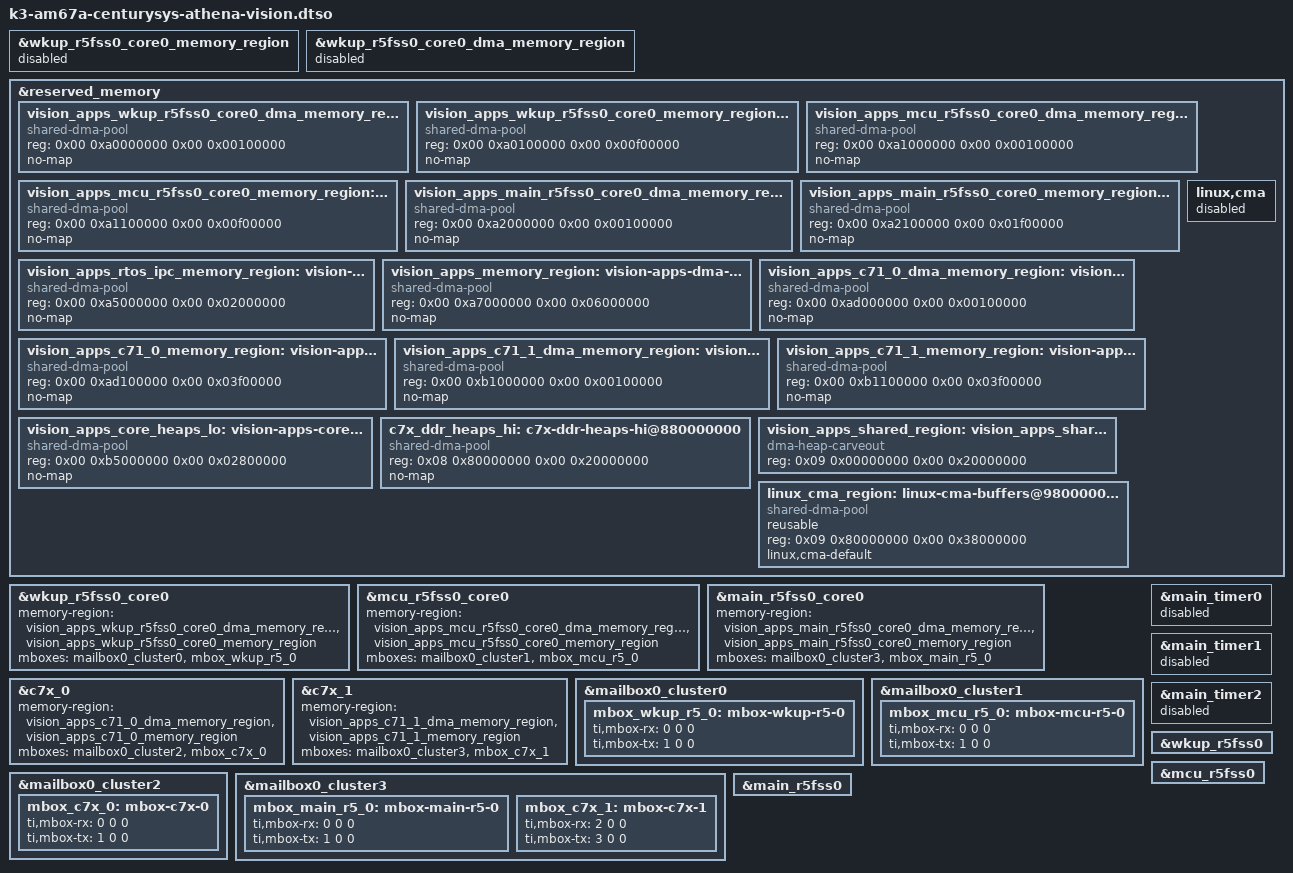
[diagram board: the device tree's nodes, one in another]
// SPDX-License-Identifier: GPL-2.0
/*
 * Vision-apps: device-tree overlay
 *
 * Copyright (C) 2019 Texas Instruments Incorporated - http://www.ti.com/
 */

#include <dt-bindings/soc/ti,sci_pm_domain.h>

/dts-v1/;
/plugin/;

&wkup_r5fss0_core0_memory_region {
	status = "disabled";
};

&wkup_r5fss0_core0_dma_memory_region {
	status = "disabled";
};

&reserved_memory {
	#address-cells = <2>;
	#size-cells = <2>;

	vision_apps_wkup_r5fss0_core0_dma_memory_region: vision-apps-r5f-dma-memory@a0000000 {
		compatible = "shared-dma-pool";
		reg = <0x00 0xa0000000 0x00 0x00100000>;
		no-map;
	};
	vision_apps_wkup_r5fss0_core0_memory_region: vision-apps-r5f-memory@a0100000 {
		compatible = "shared-dma-pool";
		reg = <0x00 0xa0100000 0x00 0x00f00000>;
		no-map;
	};
	vision_apps_mcu_r5fss0_core0_dma_memory_region: vision-apps-r5f-dma-memory@a1000000 {
		compatible = "shared-dma-pool";
		reg = <0x00 0xa1000000 0x00 0x00100000>;
		no-map;
	};
	vision_apps_mcu_r5fss0_core0_memory_region: vision-apps-r5f-memory@a1100000 {
		compatible = "shared-dma-pool";
		reg = <0x00 0xa1100000 0x00 0x00f00000>;
		no-map;
	};
	vision_apps_main_r5fss0_core0_dma_memory_region: vision-apps-r5f-dma-memory@a2000000 {
		compatible = "shared-dma-pool";
		reg = <0x00 0xa2000000 0x00 0x00100000>;
		no-map;
	};
	vision_apps_main_r5fss0_core0_memory_region: vision-apps-r5f-memory@a2100000 {
		compatible = "shared-dma-pool";
		reg = <0x00 0xa2100000 0x00 0x01f00000>;
		no-map;
	};
	vision_apps_rtos_ipc_memory_region: vision-apps-rtos-ipc-memory-region@a5000000 {
		compatible = "shared-dma-pool";
		reg = <0x00 0xa5000000 0x00 0x02000000>;
		no-map;
	};
	vision_apps_memory_region: vision-apps-dma-memory@a7000000 {
		compatible = "shared-dma-pool";
		reg = <0x00 0xa7000000 0x00 0x06000000>;
		no-map;
	};
	vision_apps_c71_0_dma_memory_region: vision-apps-c71-dma-memory@ad000000 {
		compatible = "shared-dma-pool";
		reg = <0x00 0xad000000 0x00 0x00100000>;
		no-map;
	};
	vision_apps_c71_0_memory_region: vision-apps-c71_0-memory@ad100000 {
		compatible = "shared-dma-pool";
		reg = <0x00 0xad100000 0x00 0x03f00000>;
		no-map;
	};
	vision_apps_c71_1_dma_memory_region: vision-apps-c71_1-dma-memory@b1000000 {
		compatible = "shared-dma-pool";
		reg = <0x00 0xb1000000 0x00 0x00100000>;
		no-map;
	};
	vision_apps_c71_1_memory_region: vision-apps-c71_1-memory@b1100000 {
		compatible = "shared-dma-pool";
		reg = <0x00 0xb1100000 0x00 0x03f00000>;
		no-map;
	};
	vision_apps_core_heaps_lo: vision-apps-core-heap-memory-lo@b5000000 {
		compatible = "shared-dma-pool";
		reg = <0x00 0xb5000000 0x00 0x02800000>;
		no-map;
	};
	c7x_ddr_heaps_hi: c7x-ddr-heaps-hi@880000000 {
		compatible = "shared-dma-pool";
		reg = <0x08 0x80000000 0x00 0x20000000>;
		no-map;
	};
	vision_apps_shared_region: vision_apps_shared-memories {
		compatible = "dma-heap-carveout";
		reg = <0x09 0x00000000 0x00 0x20000000>;
	};

	linux,cma {
		status = "disabled";
	};

	linux_cma_region: linux-cma-buffers@980000000 {
		compatible = "shared-dma-pool";
		reusable;
		reg = <0x09 0x80000000 0x00 0x38000000>;
		linux,cma-default;
	};
};

&wkup_r5fss0_core0 {
	memory-region = <&vision_apps_wkup_r5fss0_core0_dma_memory_region>,
			<&vision_apps_wkup_r5fss0_core0_memory_region>;
};

&mcu_r5fss0_core0 {
	memory-region = <&vision_apps_mcu_r5fss0_core0_dma_memory_region>,
			<&vision_apps_mcu_r5fss0_core0_memory_region>;
};

&main_r5fss0_core0 {
	memory-region = <&vision_apps_main_r5fss0_core0_dma_memory_region>,
			<&vision_apps_main_r5fss0_core0_memory_region>;
};

&c7x_0 {
	memory-region = <&vision_apps_c71_0_dma_memory_region>,
			<&vision_apps_c71_0_memory_region>;
};

&c7x_1 {
	memory-region = <&vision_apps_c71_1_dma_memory_region>,
			<&vision_apps_c71_1_memory_region>;
};

&mailbox0_cluster0 {
	status = "okay";

	mbox_wkup_r5_0: mbox-wkup-r5-0 {
		ti,mbox-rx = <0 0 0>;
		ti,mbox-tx = <1 0 0>;
	};
};

&mailbox0_cluster1 {
	status = "okay";

	mbox_mcu_r5_0: mbox-mcu-r5-0 {
		ti,mbox-rx = <0 0 0>;
		ti,mbox-tx = <1 0 0>;
	};
};

&mailbox0_cluster2 {
	status = "okay";

	mbox_c7x_0: mbox-c7x-0 {
		ti,mbox-rx = <0 0 0>;
		ti,mbox-tx = <1 0 0>;
	};
};

&mailbox0_cluster3 {
	status = "okay";

	mbox_main_r5_0: mbox-main-r5-0 {
		ti,mbox-rx = <0 0 0>;
		ti,mbox-tx = <1 0 0>;
	};

	mbox_c7x_1: mbox-c7x-1 {
		ti,mbox-rx = <2 0 0>;
		ti,mbox-tx = <3 0 0>;
	};
};

/* Timers are used by Remoteproc firmware */
&main_timer0 {
	status = "reserved";
};

&main_timer1 {
	status = "reserved";
};

&main_timer2 {
	status = "reserved";
};

&wkup_r5fss0 {
	status = "okay";
};

&wkup_r5fss0_core0 {
	mboxes = <&mailbox0_cluster0 &mbox_wkup_r5_0>;
	status = "okay";
};

&mcu_r5fss0 {
	status = "okay";
};

&mcu_r5fss0_core0 {
	mboxes = <&mailbox0_cluster1 &mbox_mcu_r5_0>;
	status = "okay";
};

&main_r5fss0 {
	status = "okay";
};

&main_r5fss0_core0 {
	mboxes = <&mailbox0_cluster3 &mbox_main_r5_0>;
	status = "okay";
};

&c7x_0 {
	mboxes = <&mailbox0_cluster2 &mbox_c7x_0>;
	status = "okay";
};

&c7x_1 {
	mboxes = <&mailbox0_cluster3 &mbox_c7x_1>;
	status = "okay";
};
